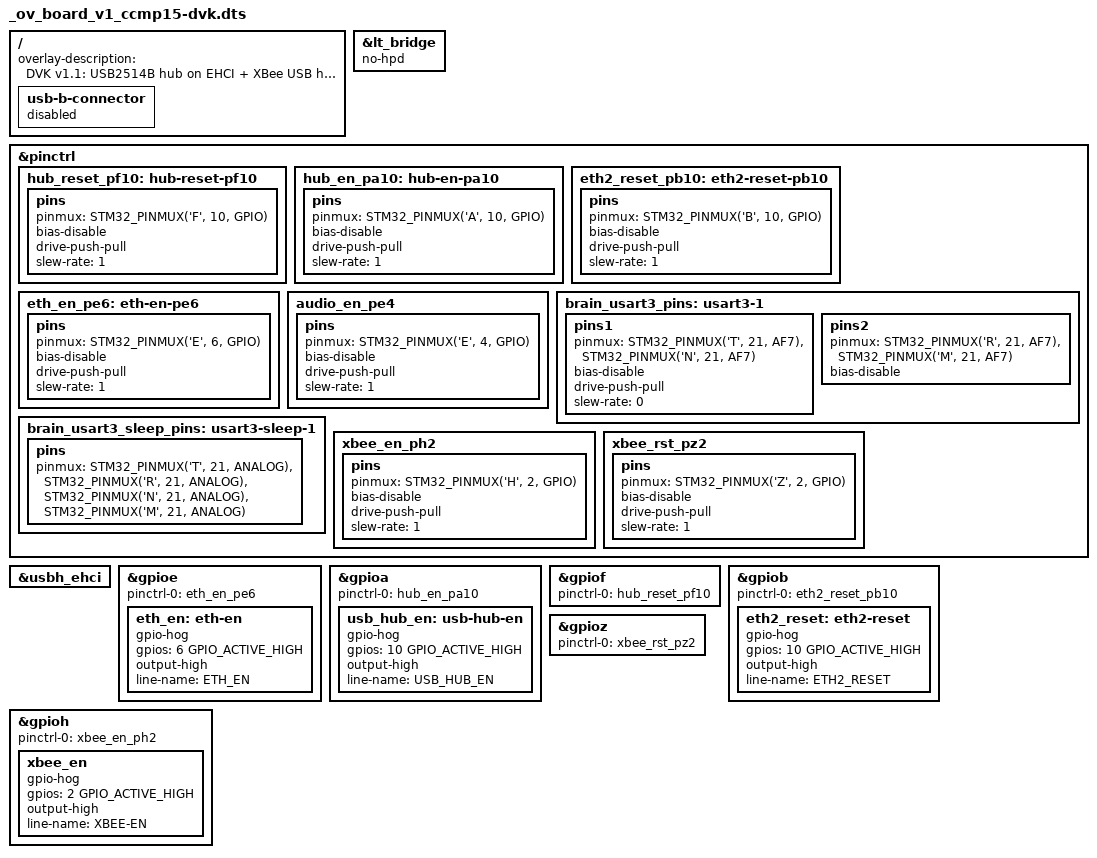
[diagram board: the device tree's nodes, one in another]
/dts-v1/;
/plugin/;

#include <dt-bindings/gpio/gpio.h>
#include <dt-bindings/pinctrl/stm32-pinfunc.h>

/ {
	fragment@0 {
		target-path = "/";
		__overlay__ {
			overlay-description = "DVK v1.1: USB2514B hub on EHCI + XBee USB host on OTG + ETH2 + XBEE";
			usb-b-connector { status = "disabled"; };
		};
	};
	
	fragment@1 {
		target = <&lt_bridge>;
	__overlay__ { no-hpd; };
	};
	
	/* Pinmux states */
	fragment@2 {
		target = <&pinctrl>;
		__overlay__ {
			hub_reset_pf10: hub-reset-pf10 {
			pins { pinmux = <STM32_PINMUX('F', 10, GPIO)>; bias-disable; drive-push-pull; slew-rate = <1>; };
			};
			hub_en_pa10: hub-en-pa10 {
			pins { pinmux = <STM32_PINMUX('A', 10, GPIO)>; bias-disable; drive-push-pull; slew-rate = <1>; };
			};
			eth2_reset_pb10: eth2-reset-pb10 {
			pins { pinmux = <STM32_PINMUX('B', 10, GPIO)>; bias-disable; drive-push-pull; slew-rate = <1>; };
			};
			eth_en_pe6: eth-en-pe6 {
			pins { pinmux = <STM32_PINMUX('E', 6, GPIO)>; bias-disable; drive-push-pull; slew-rate = <1>; };
			};
			audio_en_pe4: audio_en_pe4{
			pins { pinmux = <STM32_PINMUX('E', 4, GPIO)>; bias-disable; drive-push-pull; slew-rate = <1>; };
			};

			brain_usart3_pins: usart3-1 {
				pins1 {
					pinmux = <STM32_PINMUX('T', 21, AF7)>, /* USART3_TX */
					<STM32_PINMUX('N', 21, AF7)>; /* USART3_RTS */
					bias-disable;
					drive-push-pull;
					slew-rate = <0>;
				};
				pins2 {
					pinmux = <STM32_PINMUX('R', 21, AF7)>, /* USART3_RX */
					<STM32_PINMUX('M', 21, AF7)>; /* USART3_CTS */
					bias-disable;
				};
			};
			
			brain_usart3_sleep_pins: usart3-sleep-1 {
				pins {
					pinmux = <STM32_PINMUX('T', 21, ANALOG)>, /* USART3_TX */
					<STM32_PINMUX('R', 21, ANALOG)>, /* USART3_RX */
					<STM32_PINMUX('N', 21, ANALOG)>, /* USART3_RTS */
					<STM32_PINMUX('M', 21, ANALOG)>; /* USART3_CTS */
				};
			};
			/*Xbee pins: PH2 = xbee_en, PZ2 = xbee_rst */
			xbee_en_ph2: xbee_en_ph2 {
			pins { pinmux = <STM32_PINMUX('H', 2, GPIO)>; bias-disable; drive-push-pull; slew-rate = <1>; };
			};
			xbee_rst_pz2: xbee_rst_pz2 {
			pins { pinmux = <STM32_PINMUX('Z', 2, GPIO)>; bias-disable; drive-push-pull; slew-rate = <1>; };
			};
		};
	};
	/* Keep the USB2514B hub on the EHCI host path */
	fragment@4 {
		target = <&usbh_ehci>;
	__overlay__ { status = "okay"; };
	};
	
	/* GPIO hogs */
	fragment@5 {
		target = <&gpioe>;
		__overlay__ {
			pinctrl-names = "default";
			pinctrl-0 = <&eth_en_pe6>;
			eth_en: eth-en {
				gpio-hog;
				gpios = <6 GPIO_ACTIVE_HIGH>;
				output-high;
				line-name = "ETH_EN";
			};
		};
	};
	
	fragment@6 {
		target = <&gpioa>;
		__overlay__ {
			pinctrl-names = "default";
			pinctrl-0 = <&hub_en_pa10>;
			usb_hub_en: usb-hub-en {
				gpio-hog;
				gpios = <10 GPIO_ACTIVE_HIGH>;
				output-high;
				line-name = "USB_HUB_EN";
			};
		};
	};
	
	fragment@7 {
		target = <&gpiof>;
		__overlay__ {
			pinctrl-names = "default";
			pinctrl-0 = <&hub_reset_pf10>;
		};
	};
	
	fragment@8 {
		target = <&gpiob>;
		__overlay__ {
			pinctrl-names = "default";
			pinctrl-0 = <&eth2_reset_pb10>;
			eth2_reset: eth2-reset {
				gpio-hog;
				gpios = <10 GPIO_ACTIVE_HIGH>;
				output-high;
				line-name = "ETH2_RESET";
			};
		};
	};
    
    fragment@9 {
		target = <&gpioh>;
		__overlay__ {
			pinctrl-names = "default";
			pinctrl-0 = <&xbee_en_ph2>;
			xbee_en: xbee_en {
				gpio-hog;
				gpios = <2 GPIO_ACTIVE_HIGH>;
				output-high;
				line-name = "XBEE-EN";
			};
		};
	};
	fragment@10 {
		target = <&gpioz>;
		__overlay__ {
			pinctrl-names = "default";
			pinctrl-0 = <&xbee_rst_pz2>;
		};
	};
};
